# SR1 register map
Vendor: Texas Instruments
Peripheral module from a debugger description file (folder omap36xx).
Registers are 32-bit, access per field, reset 0x0 unless marked. A register's access mark holds for its fields unless they carry their own. Offsets are as the file gives them; lines under a group give offsets from that group; [hi:lo] are bit positions; {n}, {i} and the like mark numbered series; 'fields as' and 'values as' point back to an identical list; <NAME> marks a mode.

## SR1
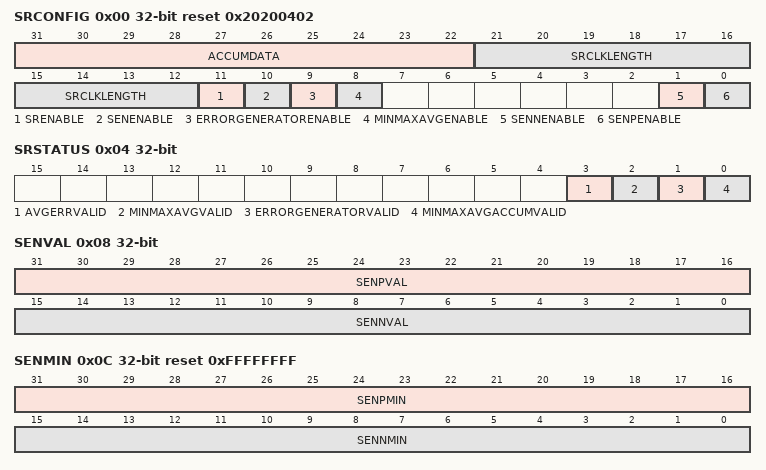
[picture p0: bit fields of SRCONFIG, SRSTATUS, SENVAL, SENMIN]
0x00 SRCONFIG rw reset 0x20200402 — This register contains configuration bits for the sensor core and digital processing
  [31:22] ACCUMDATA — Number of values to accumulate
  [21:12] SRCLKLENGTH — Determines the frequency of SRClk
  [11] SRENABLE — 0x0: Asynchronously resets MinMaxAvgAccumValid, MinMaxAvgValid, ErrorGeneratorValid, AccumData sensor, SRClk counter, and MinMaxAvg registers. Also gates the clock for power savings and disables all the digital logic.
    1=Enables the module
  [10] SENENABLE — Sensor module enable
    0=Disable all sensors; 1=Enable sensors
  [9] ERRORGENERATORENABLE — Error generator module enable
    0=Disable error generator module; 1=Enable error generator module
  [8] MINMAXAVGENABLE — Min/Max/Avg detector module enable
    0=Disable min max avg detector module; 1=Enable min max avg detector module
  [1] SENNENABLE — Enable/disable SenN sensor
    0=Disable SenN sensor; 1=Enable SenN sensor
  [0] SENPENABLE — Enable/disable SenP sensor
    0=Disable SenP sensor; 1=Enable SenP sensor
0x04 SRSTATUS ro — This register contains status bits that indicate that the values in the register are valid or events have occured
  [3] AVGERRVALID
    0=SenAvg register are not valid; 1=SenAvg register are valid
  [2] MINMAXAVGVALID
    0=SenVal, SenMin, SenMax, SenAvg registers are not valid; 1=SenVal, SenMin, SenMax, SenAvg registers are valid
  [1] ERRORGENERATORVALID
    0=SenErr register do not have valid data; 1=SenErr register have valid data
  [0] MINMAXAVGACCUMVALID
    0=SenVal, SenMin, SenMax, SenAvg registers do not have final data; 1=SenVal, SenMin, SenMax, SenAvg registers have final data
0x08 SENVAL ro — This register gives the sensor value for the sensor core
  [31:16] SENPVAL — Latest Value of SenP from sensor Core
  [15:0] SENNVAL — Latest Value of SenN from Sensor Core
0x0C SENMIN ro reset 0xFFFFFFFF — This register gives the minimum sensor value
  [31:16] SENPMIN — Minimum value of SenP
  [15:0] SENNMIN — Minimum value of SenN
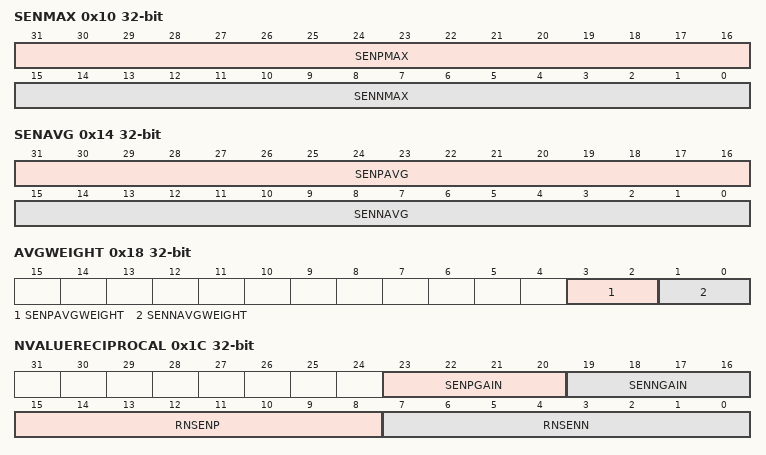
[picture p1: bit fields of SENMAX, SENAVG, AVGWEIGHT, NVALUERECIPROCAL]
0x10 SENMAX ro — This register give the maximum sensor value
  [31:16] SENPMAX — Maximum Value of SenP
  [15:0] SENNMAX — Maximum value of SenN
0x14 SENAVG ro — This register gives the average sensor values
  [31:16] SENPAVG — Running average of the SenP values
  [15:0] SENNAVG — Running average of the SenN values
0x18 AVGWEIGHT — This register gives the weighing factor in the average computation
  [3:2] SENPAVGWEIGHT rw — The weighting factor for the SenP Averager
  [1:0] SENNAVGWEIGHT rw — The weighting factor for the SenN Averager
0x1C NVALUERECIPROCAL — This Register contain the reciprocal of the SenN and SenP values used in the error generation
  [23:20] SENPGAIN rw — Gain Value Of reciprocal SenP
  [19:16] SENNGAIN rw — Gain Value of reciprocal SenN
  [15:8] RNSENP rw — The Scale value of the SenP RN reciprocal value
  [7:0] RNSENN rw — The Scale value of the SenN RN reciprocal value
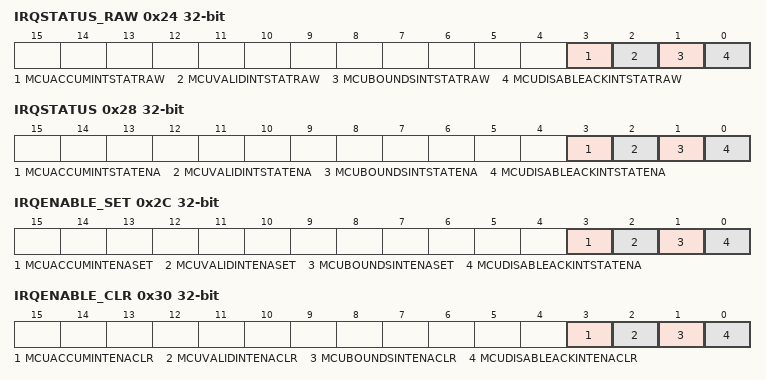
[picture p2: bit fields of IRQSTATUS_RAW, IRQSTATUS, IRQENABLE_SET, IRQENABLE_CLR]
0x24 IRQSTATUS_RAW — MCU raw interrupt status and set
  [3] MCUACCUMINTSTATRAW rw — 0: Accum interrupt status is unchanged.
    1=Accum interrupt status is set 
  [2] MCUVALIDINTSTATRAW rw — 0: Valid interrupt status is unchanged.
    1=Valid interrupt status is set
  [1] MCUBOUNDSINTSTATRAW rw — 0: Bounds interrupt status is unchanged.
    1=Bounds interrupt status is set
  [0] MCUDISABLEACKINTSTATRAW rw — 0: MCU Disable acknowledge status is unchanged.
    1=MCU Disable acknowledge status is set
0x28 IRQSTATUS — MCU masked interrupt status and clear
  [3] MCUACCUMINTSTATENA rw — Read 0: Accum interrupt status is unchanged.
    1=MCUACCUMINTSTATENA_1_r (Accum interrupt status is set.); 0=MCUACCUMINTSTATENA_0_w (Accum interrupt status is unchanged.); 1=MCUACCUMINTSTATENA_1_w (Accum interrupt status is cleared.)
  [2] MCUVALIDINTSTATENA rw — Read 0: Valid interrupt status is unchanged.
    1=MCUVALIDINTSTATENA_1_r (Valid interrupt status is set.); 0=MCUVALIDINTSTATENA_0_w (Valid interrupt status is unchanged.); 1=MCUVALIDINTSTATENA_1_w (Valid interrupt status is cleared.)
  [1] MCUBOUNDSINTSTATENA rw — Read 0: Bounds interrupt status is unchanged.
    1=MCUBOUNDSINTSTATENA_1_r (Bounds interrupt status is set.); 0=MCUBOUNDSINTSTATENA_0_w (Bounds interrupt status is unchanged.); 1=MCUBOUNDSINTSTATENA_1_w (Bounds interrupt status is cleared.)
  [0] MCUDISABLEACKINTSTATENA rw — Read 0: MCUDisable acknowledge status is unchanged.
    1=MCUDISABLEACKINTSTATENA_1_r (MCUDisable acknowledge status is set.); 0=MCUDISABLEACKINTSTATENA_0_w (MCUDisable interrupt status is unchanged.); 1=MCUDISABLEACKINTSTATENA_1_w (MCUDisable interrupt status is cleared.)
0x2C IRQENABLE_SET — MCU interrupt enable flag and set
  [3] MCUACCUMINTENASET rw — Read mode:Write mode: .
    0=Accum interrupt generation is disabled/masked; 1=Accum interrupt generation is enabled; 0=No change to Accum interrupt enable; 1=Enable Accum interrupt generation
  [2] MCUVALIDINTENASET rw — Read mode:Write mode: .
    0=Valid interrupt generation is disabled/masked; 1=Valid interrupt generation is enabled; 0=No change to valid interrupt enable; 1=Enable valid interrupt generation
  [1] MCUBOUNDSINTENASET rw — Read mode:Write mode: .
    0=Bounds interrupt generation is disabled/masked; 1=Bounds interrupt generation is enabled; 0=No change to bounds interrupt enable; 1=Enable bounds interrupt generation
  [0] MCUDISABLEACKINTSTATENA rw — Read mode:Write mode: .
    0=MCUDisableAck interrupt generation is disabled/masked; 1=MCUDisableAck interrupt generation is enabled; 0=No change to MCUDisAck interrupt enable; 1=Enable MCUDisableAck interrupt generation
0x30 IRQENABLE_CLR — MCU interrup enable flag and clear
  [3] MCUACCUMINTENACLR rw — Read mode:Write mode: .
    0=Accum interrupt generation is disabled/masked; 1=Accum interrupt generation is enabled; 0=No change to accum interrupt enable; 1=Disable accum interrupt generation
  [2] MCUVALIDINTENACLR rw — Read mode:Write mode: .
    0=Valid interrupt generation is disabled/masked; 1=Valid interrupt generation is enabled; 0=No change to valid interrupt enable; 1=Disable valid interrupt generation
  [1] MCUBOUNDSINTENACLR rw — Read mode:Write mode: .
    0=Bounds interrupt generation is disabled/masked; 1=Bounds interrupt generation is enabled; 0=No change to bounds interrupt enable; 1=Disable bounds interrupt generation
  [0] MCUDISABLEACKINTENACLR rw — Read mode:Write mode: .
    0=MCUDisableAck interrupt generation is disabled/masked; 1=MCUDisableAck interrupt generation is enabled; 0=No change to MCUDisAck interrupt enable,; 1=Disable MCUDisableAck interrupt generation
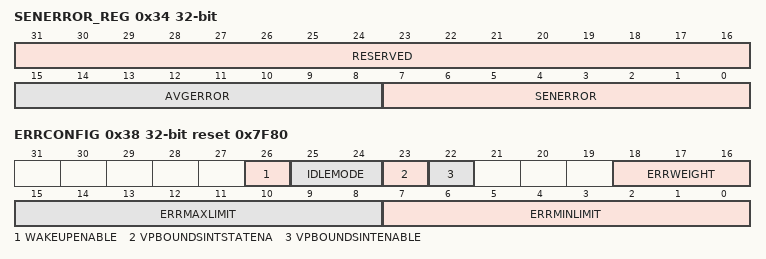
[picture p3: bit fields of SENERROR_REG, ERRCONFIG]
0x34 SENERROR_REG ro — This register gives the sensor error from the error generator
  [31:16] RESERVED — Reseved
  [15:8] AVGERROR — Average sensor error
  [7:0] SENERROR — Percentage of sensor error
0x38 ERRCONFIG reset 0x7F80 — This register is used for error configuration
  [26] WAKEUPENABLE rw — Wakeup from MCU Interrupts enable.
    0=Disables wakeup from MCU interrupts; 1=Enables wakeup from MCU interrupts
  [25:24] IDLEMODE rw — 0x0: Force-idle mode
    1=No-idle mode; 2=Smart-idle mode 2; 3=Smart-idle-wakeup mode
  [23] VPBOUNDSINTSTATENA rw — 0x0: Bounds interrupt status is unchanged.
    1=Bounds interrupt status is cleared
  [22] VPBOUNDSINTENABLE rw — 0x0: Bounds interrupt disabled
    1=Bounds interrupt enabled
  [18:16] ERRWEIGHT rw — Average Sensor Error weight
  [15:8] ERRMAXLIMIT rw — Upper limit of sensor error for interrupt generation
  [7:0] ERRMINLIMIT rw — Lower limit of sensor error for interrupt generation
